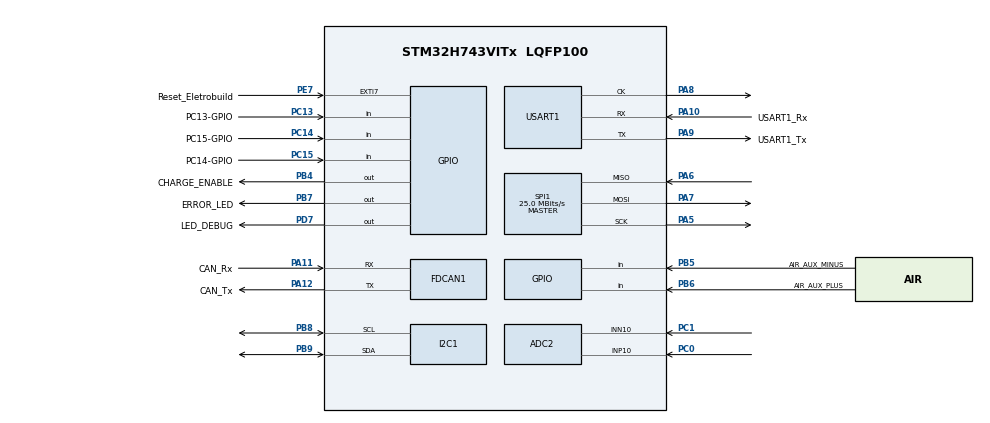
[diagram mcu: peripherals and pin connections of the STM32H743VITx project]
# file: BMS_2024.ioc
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ADC2.Channel-0\#ChannelRegularConversion=ADC_CHANNEL_10
ADC2.NbrOfConversionFlag=1
ADC2.OffsetNumber-0\#ChannelRegularConversion=ADC_OFFSET_NONE
ADC2.OffsetSignedSaturation-0\#ChannelRegularConversion=DISABLE
ADC2.Rank-0\#ChannelRegularConversion=1
ADC2.SamplingTime-0\#ChannelRegularConversion=ADC_SAMPLETIME_1CYCLE_5
ADC2.SingleDiff-0\#ChannelRegularConversion=ADC_DIFFERENTIAL_ENDED
Dma.DMA_GENERATOR0.0.Direction=DMA_PERIPH_TO_MEMORY
Dma.DMA_GENERATOR0.0.EventEnable=DISABLE
Dma.DMA_GENERATOR0.0.FIFOMode=DMA_FIFOMODE_DISABLE
Dma.DMA_GENERATOR0.0.Instance=DMA1_Stream0
Dma.DMA_GENERATOR0.0.MemDataAlignment=DMA_MDATAALIGN_BYTE
Dma.DMA_GENERATOR0.0.MemInc=DMA_MINC_ENABLE
Dma.DMA_GENERATOR0.0.Mode=DMA_NORMAL
Dma.DMA_GENERATOR0.0.PeriphDataAlignment=DMA_PDATAALIGN_BYTE
Dma.DMA_GENERATOR0.0.PeriphInc=DMA_PINC_DISABLE
Dma.DMA_GENERATOR0.0.Polarity=HAL_DMAMUX_REQ_GEN_RISING
Dma.DMA_GENERATOR0.0.Priority=DMA_PRIORITY_LOW
Dma.DMA_GENERATOR0.0.RequestNumber=1
Dma.DMA_GENERATOR0.0.SignalID=NONE
Dma.DMA_GENERATOR0.0.SyncEnable=DISABLE
Dma.DMA_GENERATOR0.0.SyncPolarity=HAL_DMAMUX_SYNC_NO_EVENT
Dma.DMA_GENERATOR0.0.SyncRequestNumber=1
Dma.DMA_GENERATOR0.0.SyncSignalID=NONE
Dma.Request0=DMA_GENERATOR0
FDCAN1.CalculateBaudRateNominal=625000
FDCAN1.CalculateTimeBitNominal=1600
FDCAN1.CalculateTimeQuantumNominal=320.0
I2C1.Timing=0x00707CBB
Mcu.Family=STM32H7
Mcu.Name=STM32H743VITx
Mcu.Package=LQFP100
NVIC.PriorityGroup=NVIC_PRIORITYGROUP_4
PA10.GPIO_Label=USART1_Rx
PA10.Mode=Synchronous
PA10.Signal=USART1_RX
PA11.GPIO_Label=CAN_Rx
PA11.Mode=FDCAN_Activate
PA11.Signal=FDCAN1_RX
PA12.GPIO_Label=CAN_Tx
PA12.Mode=FDCAN_Activate
PA12.Signal=FDCAN1_TX
PA13\ (JTMS/SWDIO).Signal=DEBUG_JTMS-SWDIO
PA14\ (JTCK/SWCLK).Signal=DEBUG_JTCK-SWCLK
PA5.Mode=Full_Duplex_Master
PA5.Signal=SPI1_SCK
PA6.Mode=Full_Duplex_Master
PA6.Signal=SPI1_MISO
PA7.Mode=Full_Duplex_Master
PA7.Signal=SPI1_MOSI
PA8.Mode=Synchronous
PA8.Signal=USART1_CK
PA9.GPIO_Label=USART1_Tx
PA9.Mode=Synchronous
PA9.Signal=USART1_TX
PB10.Signal=I2S2_CK
PB11.Signal=I2C2_SDA
PB4\ (NJTRST).GPIO_Label=CHARGE_ENABLE
PB4\ (NJTRST).Signal=GPIO_Output
PB5.GPIO_Label=AIR_AUX_MINUS
PB5.Signal=GPIO_Input
PB6.GPIO_Label=AIR_AUX_PLUS
PB6.Signal=GPIO_Input
PB7.GPIO_Label=ERROR_LED
PB7.Signal=GPIO_Output
PB8.Mode=I2C
PB8.Signal=I2C1_SCL
PB9.Mode=I2C
PB9.Signal=I2C1_SDA
PC0.Signal=ADCx_INP10
PC1.Signal=ADCx_INN10
PC13.GPIO_Label=PC13-GPIO
PC13.Signal=GPIO_Input
PC14-OSC32_IN\ (OSC32_IN).GPIO_Label=PC15-GPIO
PC14-OSC32_IN\ (OSC32_IN).Signal=GPIO_Input
PC15-OSC32_OUT\ (OSC32_OUT).GPIO_Label=PC14-GPIO
PC15-OSC32_OUT\ (OSC32_OUT).Signal=GPIO_Input
PD7.GPIO_Label=LED_DEBUG
PD7.Signal=GPIO_Output
PE7.GPIO_Label=Reset_Eletrobuild
PE7.Signal=GPXTI7
PH0-OSC_IN\ (PH0).Mode=HSE-External-Oscillator
PH0-OSC_IN\ (PH0).Signal=RCC_OSC_IN
PH1-OSC_OUT\ (PH1).Mode=HSE-External-Oscillator
PH1-OSC_OUT\ (PH1).Signal=RCC_OSC_OUT
ProjectManager.HeapSize=0x200
ProjectManager.StackSize=0x400
ProjectManager.TargetToolchain=STM32CubeIDE
RCC.ADCFreq_Value=37500000
RCC.APB1Freq_Value=32000000
RCC.APB2Freq_Value=32000000
RCC.APB3Freq_Value=64000000
RCC.APB4Freq_Value=64000000
RCC.CortexFreq_Value=64000000
RCC.D2PPRE1=RCC_APB1_DIV2
RCC.D2PPRE2=RCC_APB2_DIV2
RCC.DIVM1=4
RCC.DIVM2=4
RCC.DIVN1=9
RCC.DIVN2=9
RCC.DIVP2=4
RCC.DIVQ1=3
RCC.HCLKFreq_Value=64000000
RCC.PLL2FRACN=3072
RCC.PLL3FRACN=0
RCC.PLLFRACN=3072
RCC.SYSCLKFreq_VALUE=64000000
RCC.USBFreq_Value=50000000
SH.ADCx_INN10.0=ADC2_INN10,IN10-Differential
SH.ADCx_INP10.0=ADC1_INP10
SH.ADCx_INP10.1=ADC2_INP10,IN10-Differential
SPI1.CalculateBaudRate=25.0 MBits/s
SPI1.Direction=SPI_DIRECTION_2LINES
SPI1.Mode=SPI_MODE_MASTER
SPI1.VirtualType=VM_MASTER
USART1.VirtualMode-Synchronous=VM_SYNC
board=custom

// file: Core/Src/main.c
/* USER CODE BEGIN Header */
/**
  ******************************************************************************
  * @file           : main.c
  * @brief          : Main program body
  ******************************************************************************
  * @attention
  *
  * Copyright (c) 2023 STMicroelectronics.
  * All rights reserved.
  *
  * This software is licensed under terms that can be found in the LICENSE file
  * in the root directory of this software component.
  * If no LICENSE file comes with this software, it is provided AS-IS.
  *
  ******************************************************************************
  */
/* USER CODE END Header */
#include "main.h"

/* USER CODE BEGIN Includes */
#include "bms.h"
/* USER CODE END Includes */

ADC_HandleTypeDef hadc2;

FDCAN_HandleTypeDef hfdcan1;

I2C_HandleTypeDef hi2c1;

SPI_HandleTypeDef hspi1;

USART_HandleTypeDef husart1;

DMA_HandleTypeDef hdma_dma_generator0;

void SystemClock_Config(void);
static void MX_GPIO_Init(void);
static void MX_ADC2_Init(void);
static void MX_FDCAN1_Init(void);
static void MX_SPI1_Init(void);
static void MX_DMA_Init(void);
static void MX_I2C1_Init(void);
static void MX_USART1_Init(void);

int main(void)
{

  /* MCU Configuration--------------------------------------------------------*/

  /* Reset of all peripherals, Initializes the Flash interface and the Systick. */
  HAL_Init();

  /* Configure the system clock */
  SystemClock_Config();

  /* Initialize all configured peripherals */
  MX_GPIO_Init();
  MX_ADC2_Init();
  MX_FDCAN1_Init();
  MX_SPI1_Init();
  MX_DMA_Init();
  MX_I2C1_Init();
  MX_USART1_Init();
  /* USER CODE BEGIN 2 */
  Master* BMS;
  BMS_Init(&BMS);
  /* USER CODE END 2 */

  /* Infinite loop */
  /* USER CODE BEGIN WHILE */
  while (1)
  {
	  ElectricalManagement(BMS);
    /* USER CODE END WHILE */
  }
}

void SystemClock_Config(void)
{
  RCC_OscInitTypeDef RCC_OscInitStruct = {0};
  RCC_ClkInitTypeDef RCC_ClkInitStruct = {0};

  /** Supply configuration update enable
  */
  HAL_PWREx_ConfigSupply(PWR_LDO_SUPPLY);

  /** Configure the main internal regulator output voltage
  */
  __HAL_PWR_VOLTAGESCALING_CONFIG(PWR_REGULATOR_VOLTAGE_SCALE3);

  while(!__HAL_PWR_GET_FLAG(PWR_FLAG_VOSRDY)) {}

  /** Macro to configure the PLL clock source
  */
  __HAL_RCC_PLL_PLLSOURCE_CONFIG(RCC_PLLSOURCE_HSI);

  /** Initializes the RCC Oscillators according to the specified parameters
  * in the RCC_OscInitTypeDef structure.
  */
  RCC_OscInitStruct.OscillatorType = RCC_OSCILLATORTYPE_HSI;
  RCC_OscInitStruct.HSIState = RCC_HSI_DIV1;
  RCC_OscInitStruct.HSICalibrationValue = RCC_HSICALIBRATION_DEFAULT;
  RCC_OscInitStruct.PLL.PLLState = RCC_PLL_ON;
  RCC_OscInitStruct.PLL.PLLSource = RCC_PLLSOURCE_HSI;
  RCC_OscInitStruct.PLL.PLLM = 4;
  RCC_OscInitStruct.PLL.PLLN = 9;
  RCC_OscInitStruct.PLL.PLLP = 2;
  RCC_OscInitStruct.PLL.PLLQ = 3;
  RCC_OscInitStruct.PLL.PLLR = 2;
  RCC_OscInitStruct.PLL.PLLRGE = RCC_PLL1VCIRANGE_3;
  RCC_OscInitStruct.PLL.PLLVCOSEL = RCC_PLL1VCOMEDIUM;
  RCC_OscInitStruct.PLL.PLLFRACN = 3072;
  if (HAL_RCC_OscConfig(&RCC_OscInitStruct) != HAL_OK)
  {
    Error_Handler();
  }

  /** Initializes the CPU, AHB and APB buses clocks
  */
  RCC_ClkInitStruct.ClockType = RCC_CLOCKTYPE_HCLK|RCC_CLOCKTYPE_SYSCLK
                              |RCC_CLOCKTYPE_PCLK1|RCC_CLOCKTYPE_PCLK2
                              |RCC_CLOCKTYPE_D3PCLK1|RCC_CLOCKTYPE_D1PCLK1;
  RCC_ClkInitStruct.SYSCLKSource = RCC_SYSCLKSOURCE_HSI;
  RCC_ClkInitStruct.SYSCLKDivider = RCC_SYSCLK_DIV1;
  RCC_ClkInitStruct.AHBCLKDivider = RCC_HCLK_DIV1;
  RCC_ClkInitStruct.APB3CLKDivider = RCC_APB3_DIV1;
  RCC_ClkInitStruct.APB1CLKDivider = RCC_APB1_DIV2;
  RCC_ClkInitStruct.APB2CLKDivider = RCC_APB2_DIV2;
  RCC_ClkInitStruct.APB4CLKDivider = RCC_APB4_DIV1;

  if (HAL_RCC_ClockConfig(&RCC_ClkInitStruct, FLASH_LATENCY_1) != HAL_OK)
  {
    Error_Handler();
  }
}

static void MX_ADC2_Init(void)
{

  ADC_ChannelConfTypeDef sConfig = {0};

  /** Common config
  */
  hadc2.Instance = ADC2;
  hadc2.Init.ClockPrescaler = ADC_CLOCK_ASYNC_DIV1;
  hadc2.Init.Resolution = ADC_RESOLUTION_16B;
  hadc2.Init.ScanConvMode = ADC_SCAN_DISABLE;
  hadc2.Init.EOCSelection = ADC_EOC_SINGLE_CONV;
  hadc2.Init.LowPowerAutoWait = DISABLE;
  hadc2.Init.ContinuousConvMode = DISABLE;
  hadc2.Init.NbrOfConversion = 1;
  hadc2.Init.DiscontinuousConvMode = DISABLE;
  hadc2.Init.ExternalTrigConv = ADC_SOFTWARE_START;
  hadc2.Init.ExternalTrigConvEdge = ADC_EXTERNALTRIGCONVEDGE_NONE;
  hadc2.Init.ConversionDataManagement = ADC_CONVERSIONDATA_DR;
  hadc2.Init.Overrun = ADC_OVR_DATA_PRESERVED;
  hadc2.Init.LeftBitShift = ADC_LEFTBITSHIFT_NONE;
  hadc2.Init.OversamplingMode = DISABLE;
  if (HAL_ADC_Init(&hadc2) != HAL_OK)
  {
    Error_Handler();
  }

  /** Configure Regular Channel
  */
  sConfig.Channel = ADC_CHANNEL_10;
  sConfig.Rank = ADC_REGULAR_RANK_1;
  sConfig.SamplingTime = ADC_SAMPLETIME_1CYCLE_5;
  sConfig.SingleDiff = ADC_DIFFERENTIAL_ENDED;
  sConfig.OffsetNumber = ADC_OFFSET_NONE;
  sConfig.Offset = 0;
  sConfig.OffsetSignedSaturation = DISABLE;
  if (HAL_ADC_ConfigChannel(&hadc2, &sConfig) != HAL_OK)
  {
    Error_Handler();
  }

}

static void MX_FDCAN1_Init(void)
{

  hfdcan1.Instance = FDCAN1;
  hfdcan1.Init.FrameFormat = FDCAN_FRAME_CLASSIC;
  hfdcan1.Init.Mode = FDCAN_MODE_NORMAL;
  hfdcan1.Init.AutoRetransmission = DISABLE;
  hfdcan1.Init.TransmitPause = DISABLE;
  hfdcan1.Init.ProtocolException = DISABLE;
  hfdcan1.Init.NominalPrescaler = 16;
  hfdcan1.Init.NominalSyncJumpWidth = 1;
  hfdcan1.Init.NominalTimeSeg1 = 2;
  hfdcan1.Init.NominalTimeSeg2 = 2;
  hfdcan1.Init.DataPrescaler = 1;
  hfdcan1.Init.DataSyncJumpWidth = 1;
  hfdcan1.Init.DataTimeSeg1 = 1;
  hfdcan1.Init.DataTimeSeg2 = 1;
  hfdcan1.Init.MessageRAMOffset = 0;
  hfdcan1.Init.StdFiltersNbr = 0;
  hfdcan1.Init.ExtFiltersNbr = 0;
  hfdcan1.Init.RxFifo0ElmtsNbr = 0;
  hfdcan1.Init.RxFifo0ElmtSize = FDCAN_DATA_BYTES_8;
  hfdcan1.Init.RxFifo1ElmtsNbr = 0;
  hfdcan1.Init.RxFifo1ElmtSize = FDCAN_DATA_BYTES_8;
  hfdcan1.Init.RxBuffersNbr = 0;
  hfdcan1.Init.RxBufferSize = FDCAN_DATA_BYTES_8;
  hfdcan1.Init.TxEventsNbr = 0;
  hfdcan1.Init.TxBuffersNbr = 0;
  hfdcan1.Init.TxFifoQueueElmtsNbr = 0;
  hfdcan1.Init.TxFifoQueueMode = FDCAN_TX_FIFO_OPERATION;
  hfdcan1.Init.TxElmtSize = FDCAN_DATA_BYTES_8;
  if (HAL_FDCAN_Init(&hfdcan1) != HAL_OK)
  {
    Error_Handler();
  }

}

static void MX_I2C1_Init(void)
{

  hi2c1.Instance = I2C1;
  hi2c1.Init.Timing = 0x00707CBB;
  hi2c1.Init.OwnAddress1 = 0;
  hi2c1.Init.AddressingMode = I2C_ADDRESSINGMODE_7BIT;
  hi2c1.Init.DualAddressMode = I2C_DUALADDRESS_DISABLE;
  hi2c1.Init.OwnAddress2 = 0;
  hi2c1.Init.OwnAddress2Masks = I2C_OA2_NOMASK;
  hi2c1.Init.GeneralCallMode = I2C_GENERALCALL_DISABLE;
  hi2c1.Init.NoStretchMode = I2C_NOSTRETCH_DISABLE;
  if (HAL_I2C_Init(&hi2c1) != HAL_OK)
  {
    Error_Handler();
  }

  /** Configure Analogue filter
  */
  if (HAL_I2CEx_ConfigAnalogFilter(&hi2c1, I2C_ANALOGFILTER_ENABLE) != HAL_OK)
  {
    Error_Handler();
  }

  /** Configure Digital filter
  */
  if (HAL_I2CEx_ConfigDigitalFilter(&hi2c1, 0) != HAL_OK)
  {
    Error_Handler();
  }

}

static void MX_SPI1_Init(void)
{

  /* SPI1 parameter configuration*/
  hspi1.Instance = SPI1;
  hspi1.Init.Mode = SPI_MODE_MASTER;
  hspi1.Init.Direction = SPI_DIRECTION_2LINES;
  hspi1.Init.DataSize = SPI_DATASIZE_4BIT;
  hspi1.Init.CLKPolarity = SPI_POLARITY_LOW;
  hspi1.Init.CLKPhase = SPI_PHASE_1EDGE;
  hspi1.Init.NSS = SPI_NSS_SOFT;
  hspi1.Init.BaudRatePrescaler = SPI_BAUDRATEPRESCALER_2;
  hspi1.Init.FirstBit = SPI_FIRSTBIT_MSB;
  hspi1.Init.TIMode = SPI_TIMODE_DISABLE;
  hspi1.Init.CRCCalculation = SPI_CRCCALCULATION_DISABLE;
  hspi1.Init.CRCPolynomial = 0x0;
  hspi1.Init.NSSPMode = SPI_NSS_PULSE_ENABLE;
  hspi1.Init.NSSPolarity = SPI_NSS_POLARITY_LOW;
  hspi1.Init.FifoThreshold = SPI_FIFO_THRESHOLD_01DATA;
  hspi1.Init.TxCRCInitializationPattern = SPI_CRC_INITIALIZATION_ALL_ZERO_PATTERN;
  hspi1.Init.RxCRCInitializationPattern = SPI_CRC_INITIALIZATION_ALL_ZERO_PATTERN;
  hspi1.Init.MasterSSIdleness = SPI_MASTER_SS_IDLENESS_00CYCLE;
  hspi1.Init.MasterInterDataIdleness = SPI_MASTER_INTERDATA_IDLENESS_00CYCLE;
  hspi1.Init.MasterReceiverAutoSusp = SPI_MASTER_RX_AUTOSUSP_DISABLE;
  hspi1.Init.MasterKeepIOState = SPI_MASTER_KEEP_IO_STATE_DISABLE;
  hspi1.Init.IOSwap = SPI_IO_SWAP_DISABLE;
  if (HAL_SPI_Init(&hspi1) != HAL_OK)
  {
    Error_Handler();
  }

}

static void MX_USART1_Init(void)
{

  husart1.Instance = USART1;
  husart1.Init.BaudRate = 115200;
  husart1.Init.WordLength = USART_WORDLENGTH_8B;
  husart1.Init.StopBits = USART_STOPBITS_1;
  husart1.Init.Parity = USART_PARITY_NONE;
  husart1.Init.Mode = USART_MODE_TX_RX;
  husart1.Init.CLKPolarity = USART_POLARITY_LOW;
  husart1.Init.CLKPhase = USART_PHASE_1EDGE;
  husart1.Init.CLKLastBit = USART_LASTBIT_DISABLE;
  husart1.Init.ClockPrescaler = USART_PRESCALER_DIV1;
  husart1.SlaveMode = USART_SLAVEMODE_DISABLE;
  if (HAL_USART_Init(&husart1) != HAL_OK)
  {
    Error_Handler();
  }
  if (HAL_USARTEx_SetTxFifoThreshold(&husart1, USART_TXFIFO_THRESHOLD_1_8) != HAL_OK)
  {
    Error_Handler();
  }
  if (HAL_USARTEx_SetRxFifoThreshold(&husart1, USART_RXFIFO_THRESHOLD_1_8) != HAL_OK)
  {
    Error_Handler();
  }
  if (HAL_USARTEx_DisableFifoMode(&husart1) != HAL_OK)
  {
    Error_Handler();
  }

}

static void MX_DMA_Init(void)
{

  /* DMA controller clock enable */
  __HAL_RCC_DMA1_CLK_ENABLE();

  /* Configure DMA request hdma_dma_generator0 on DMA1_Stream0 */
  hdma_dma_generator0.Instance = DMA1_Stream0;
  hdma_dma_generator0.Init.Request = DMA_REQUEST_GENERATOR0;
  hdma_dma_generator0.Init.Direction = DMA_PERIPH_TO_MEMORY;
  hdma_dma_generator0.Init.PeriphInc = DMA_PINC_DISABLE;
  hdma_dma_generator0.Init.MemInc = DMA_MINC_ENABLE;
  hdma_dma_generator0.Init.PeriphDataAlignment = DMA_PDATAALIGN_BYTE;
  hdma_dma_generator0.Init.MemDataAlignment = DMA_MDATAALIGN_BYTE;
  hdma_dma_generator0.Init.Mode = DMA_NORMAL;
  hdma_dma_generator0.Init.Priority = DMA_PRIORITY_LOW;
  hdma_dma_generator0.Init.FIFOMode = DMA_FIFOMODE_DISABLE;
  if (HAL_DMA_Init(&hdma_dma_generator0) != HAL_OK)
  {
    Error_Handler( );
  }

}

static void MX_GPIO_Init(void)
{
  GPIO_InitTypeDef GPIO_InitStruct = {0};

  /* GPIO Ports Clock Enable */
  __HAL_RCC_GPIOC_CLK_ENABLE();
  __HAL_RCC_GPIOH_CLK_ENABLE();
  __HAL_RCC_GPIOA_CLK_ENABLE();
  __HAL_RCC_GPIOE_CLK_ENABLE();
  __HAL_RCC_GPIOB_CLK_ENABLE();
  __HAL_RCC_GPIOD_CLK_ENABLE();

  /*Configure GPIO pin Output Level */
  HAL_GPIO_WritePin(LED_DEBUG_GPIO_Port, LED_DEBUG_Pin, GPIO_PIN_RESET);

  /*Configure GPIO pin Output Level */
  HAL_GPIO_WritePin(GPIOB, CHARGE_ENABLE_Pin|ERROR_LED_Pin, GPIO_PIN_RESET);

  /*Configure GPIO pins : PC13_GPIO_Pin PC15_GPIO_Pin PC14_GPIO_Pin */
  GPIO_InitStruct.Pin = PC13_GPIO_Pin|PC15_GPIO_Pin|PC14_GPIO_Pin;
  GPIO_InitStruct.Mode = GPIO_MODE_INPUT;
  GPIO_InitStruct.Pull = GPIO_NOPULL;
  HAL_GPIO_Init(GPIOC, &GPIO_InitStruct);

  /*Configure GPIO pin : PC0 */
  GPIO_InitStruct.Pin = GPIO_PIN_0;
  GPIO_InitStruct.Mode = GPIO_MODE_ANALOG;
  GPIO_InitStruct.Pull = GPIO_NOPULL;
  HAL_GPIO_Init(GPIOC, &GPIO_InitStruct);

  /*Configure GPIO pin : Reset_Eletrobuild_Pin */
  GPIO_InitStruct.Pin = Reset_Eletrobuild_Pin;
  GPIO_InitStruct.Mode = GPIO_MODE_IT_RISING;
  GPIO_InitStruct.Pull = GPIO_NOPULL;
  HAL_GPIO_Init(Reset_Eletrobuild_GPIO_Port, &GPIO_InitStruct);

  /*Configure GPIO pin : PB10 */
  GPIO_InitStruct.Pin = GPIO_PIN_10;
  GPIO_InitStruct.Mode = GPIO_MODE_AF_PP;
  GPIO_InitStruct.Pull = GPIO_NOPULL;
  GPIO_InitStruct.Speed = GPIO_SPEED_FREQ_LOW;
  GPIO_InitStruct.Alternate = GPIO_AF5_SPI2;
  HAL_GPIO_Init(GPIOB, &GPIO_InitStruct);

  /*Configure GPIO pin : PB11 */
  GPIO_InitStruct.Pin = GPIO_PIN_11;
  GPIO_InitStruct.Mode = GPIO_MODE_AF_OD;
  GPIO_InitStruct.Pull = GPIO_NOPULL;
  GPIO_InitStruct.Speed = GPIO_SPEED_FREQ_LOW;
  GPIO_InitStruct.Alternate = GPIO_AF4_I2C2;
  HAL_GPIO_Init(GPIOB, &GPIO_InitStruct);

  /*Configure GPIO pin : LED_DEBUG_Pin */
  GPIO_InitStruct.Pin = LED_DEBUG_Pin;
  GPIO_InitStruct.Mode = GPIO_MODE_OUTPUT_PP;
  GPIO_InitStruct.Pull = GPIO_NOPULL;
  GPIO_InitStruct.Speed = GPIO_SPEED_FREQ_LOW;
  HAL_GPIO_Init(LED_DEBUG_GPIO_Port, &GPIO_InitStruct);

  /*Configure GPIO pins : CHARGE_ENABLE_Pin ERROR_LED_Pin */
  GPIO_InitStruct.Pin = CHARGE_ENABLE_Pin|ERROR_LED_Pin;
  GPIO_InitStruct.Mode = GPIO_MODE_OUTPUT_PP;
  GPIO_InitStruct.Pull = GPIO_NOPULL;
  GPIO_InitStruct.Speed = GPIO_SPEED_FREQ_LOW;
  HAL_GPIO_Init(GPIOB, &GPIO_InitStruct);

  /*Configure GPIO pins : AIR_AUX_MINUS_Pin AIR_AUX_PLUS_Pin */
  GPIO_InitStruct.Pin = AIR_AUX_MINUS_Pin|AIR_AUX_PLUS_Pin;
  GPIO_InitStruct.Mode = GPIO_MODE_INPUT;
  GPIO_InitStruct.Pull = GPIO_NOPULL;
  HAL_GPIO_Init(GPIOB, &GPIO_InitStruct);

}

void Error_Handler(void)
{
  __disable_irq();
  while (1)
  {
  }
}
